# STM32G070 register map
File version: 1.4
CPU: CM0 r0p1, little endian, MPU, no FPU, 2 interrupt priority bits
Registers are 32-bit, read-write, reset 0x0 unless marked. A register's access mark holds for its fields unless they carry their own. Offsets are from the block's base; [hi:lo] are bit positions; {n}, {i} and the like mark numbered series.

## GPIOA — General-purpose I/Os
Base 0x50000000
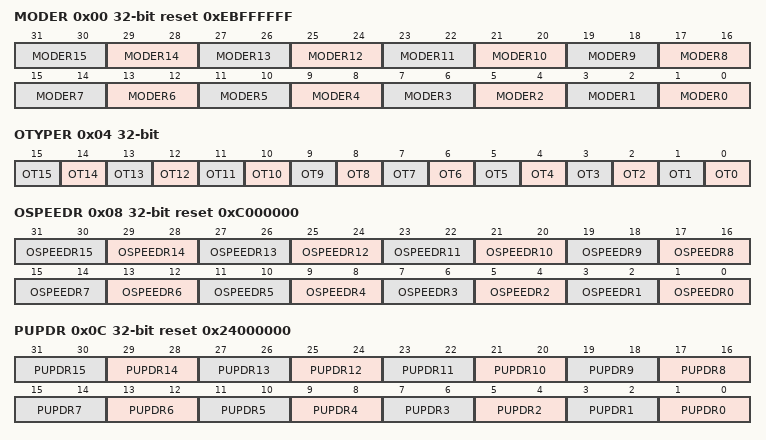
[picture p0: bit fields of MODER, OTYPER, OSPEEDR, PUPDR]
0x00 MODER reset 0xEBFFFFFF — GPIO port mode register
  [2n+1:2n] MODER{n} (n=0..15) — Port x configuration bits (y = 0..15)
0x04 OTYPER — GPIO port output type register
  [n] OT{n} (n=0..15) — Port x configuration bits (y = 0..15)
0x08 OSPEEDR reset 0xC000000 — GPIO port output speed register
  [2n+1:2n] OSPEEDR{n} (n=0..15) — Port x configuration bits (y = 0..15)
0x0C PUPDR reset 0x24000000 — GPIO port pull-up/pull-down register
  [2n+1:2n] PUPDR{n} (n=0..15) — Port x configuration bits (y = 0..15)
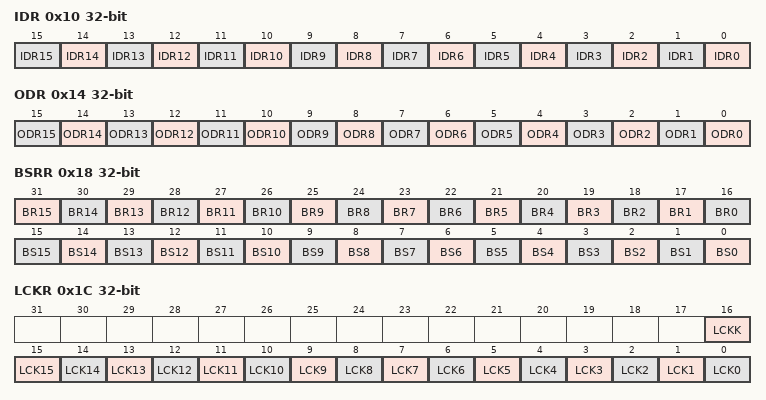
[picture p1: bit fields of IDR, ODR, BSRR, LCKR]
0x10 IDR ro — GPIO port input data register
  [n] IDR{n} (n=0..15) — Port input data (y = 0..15)
0x14 ODR — GPIO port output data register
  [n] ODR{n} (n=0..15) — Port output data (y = 0..15)
0x18 BSRR wo — GPIO port bit set/reset register
  [n+16] BR{n} (n=1..15) — Port x reset bit y (y = 0..15)
  [16] BR0 — Port x set bit y (y= 0..15)
  [n] BS{n} (n=0..15) — Port x set bit y (y= 0..15)
0x1C LCKR — GPIO port configuration lock register
  [16] LCKK — Port x lock bit y (y= 0..15)
  [n] LCK{n} (n=0..15) — Port x lock bit y (y= 0..15)
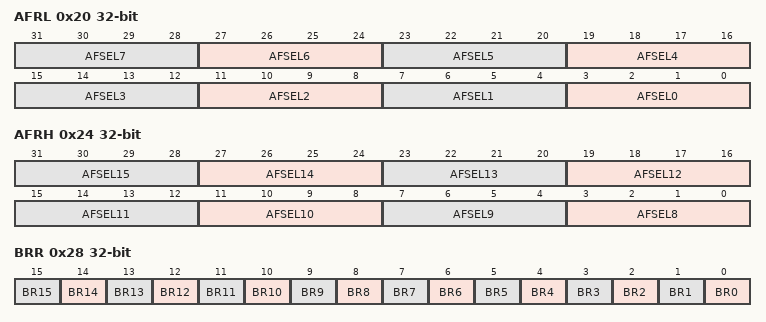
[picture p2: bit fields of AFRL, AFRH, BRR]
0x20 AFRL — GPIO alternate function low register
  [4n+3:4n] AFSEL{n} (n=0..7) — Alternate function selection for port x bit y (y = 0..7)
0x24 AFRH — GPIO alternate function high register
  [4n-29:4n-32] AFSEL{n} (n=8..15) — Alternate function selection for port x bit y (y = 8..15)
0x28 BRR wo — port bit reset register
  [n] BR{n} (n=0..15) — Port Reset bit

## GPIOB — General-purpose I/Os
Base 0x50000400
Same registers: GPIOC 0x50000800, GPIOD 0x50000C00, GPIOF 0x50001400
Registers as GPIOA; these are added or differ:
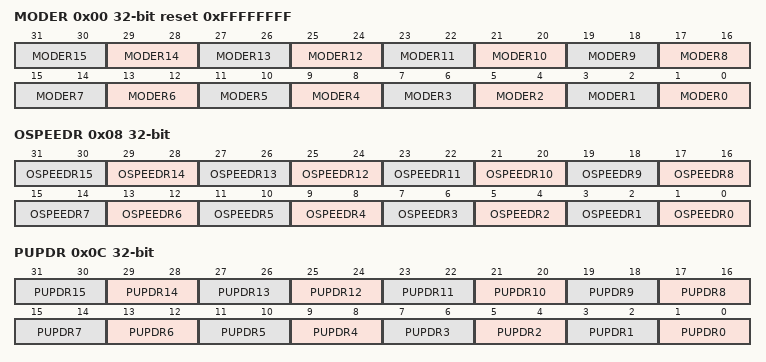
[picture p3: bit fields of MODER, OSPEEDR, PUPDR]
0x00 MODER reset 0xFFFFFFFF — GPIO port mode register
  [2n+1:2n] MODER{n} (n=0..15) — Port x configuration bits (y = 0..15)
0x08 OSPEEDR — GPIO port output speed register
  [2n+1:2n] OSPEEDR{n} (n=0..15) — Port x configuration bits (y = 0..15)
0x0C PUPDR — GPIO port pull-up/pull-down register
  [2n+1:2n] PUPDR{n} (n=0..15) — Port x configuration bits (y = 0..15)

## CRC — Cyclic redundancy check calculation unit
Base 0x40023000
0x00 DR reset 0xFFFFFFFF — Data register
  [31:0] DR — Data register bits
0x04 IDR — Independent data register
  [31:0] IDR — General-purpose 32-bit data register bits
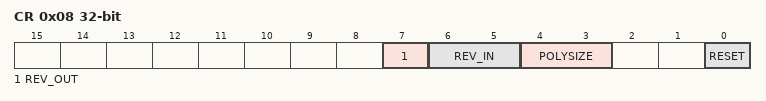
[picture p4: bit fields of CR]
0x08 CR access per field — Control register
  [7] REV_OUT rw — Reverse output data
  [6:5] REV_IN rw — Reverse input data
  [4:3] POLYSIZE rw — Polynomial size
  [0] RESET wo — RESET bit
0x10 INIT reset 0xFFFFFFFF — Initial CRC value
  [31:0] CRC_INIT — Programmable initial CRC value
0x14 POL reset 0x4C11DB7 — polynomial
  [31:0] POL — Programmable polynomial

## SPI1 — Serial peripheral interface/Inter-IC sound
Base 0x40013000
Same registers: SPI2 0x40003800
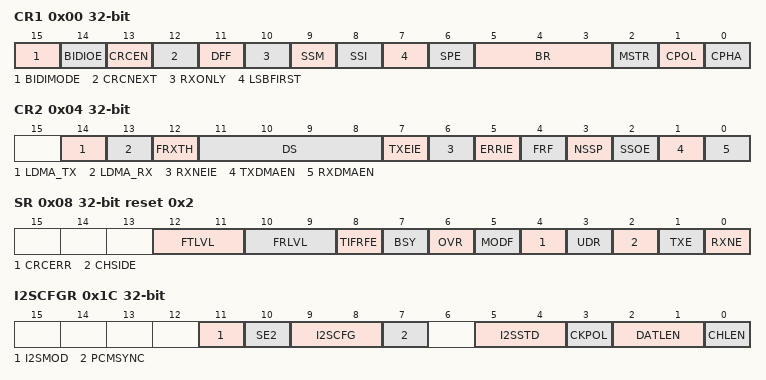
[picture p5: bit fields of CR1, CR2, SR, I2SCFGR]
0x00 CR1 — control register 1
  [15] BIDIMODE — Bidirectional data mode enable
  [14] BIDIOE — Output enable in bidirectional mode
  [13] CRCEN — Hardware CRC calculation enable
  [12] CRCNEXT — CRC transfer next
  [11] DFF — Data frame format
  [10] RXONLY — Receive only
  [9] SSM — Software slave management
  [8] SSI — Internal slave select
  [7] LSBFIRST — Frame format
  [6] SPE — SPI enable
  [5:3] BR — Baud rate control
  [2] MSTR — Master selection
  [1] CPOL — Clock polarity
  [0] CPHA — Clock phase
0x04 CR2 — control register 2
  [14] LDMA_TX — Last DMA transfer for transmission
  [13] LDMA_RX — Last DMA transfer for reception
  [12] FRXTH — FIFO reception threshold
  [11:8] DS — Data size
  [7] TXEIE — Tx buffer empty interrupt enable
  [6] RXNEIE — RX buffer not empty interrupt enable
  [5] ERRIE — Error interrupt enable
  [4] FRF — Frame format
  [3] NSSP — NSS pulse management
  [2] SSOE — SS output enable
  [1] TXDMAEN — Tx buffer DMA enable
  [0] RXDMAEN — Rx buffer DMA enable
0x08 SR access per field reset 0x2 — status register
  [12:11] FTLVL ro — FIFO transmission level
  [10:9] FRLVL ro — FIFO reception level
  [8] TIFRFE ro — TI frame format error
  [7] BSY ro — Busy flag
  [6] OVR ro — Overrun flag
  [5] MODF ro — Mode fault
  [4] CRCERR rw — CRC error flag
  [3] UDR ro — Underrun flag
  [2] CHSIDE ro — Channel side
  [1] TXE ro — Transmit buffer empty
  [0] RXNE ro — Receive buffer not empty
0x0C DR — data register
  [15:0] DR — Data register
0x10 CRCPR reset 0x7 — CRC polynomial register
  [15:0] CRCPOLY
0x14 RXCRCR ro — RX CRC register
  [15:0] RxCRC
0x18 TXCRCR ro — TX CRC register
  [15:0] TxCRC
0x1C I2SCFGR — configuration register
  [11] I2SMOD — I2S mode selection
  [10] SE2 — I2S enable
  [9:8] I2SCFG — I2S configuration mode
  [7] PCMSYNC — PCM frame synchronization
  [5:4] I2SSTD — standard selection
  [3] CKPOL — Inactive state clock polarity
  [2:1] DATLEN — Data length to be transferred
  [0] CHLEN — Channel length (number of bits per audio channel)
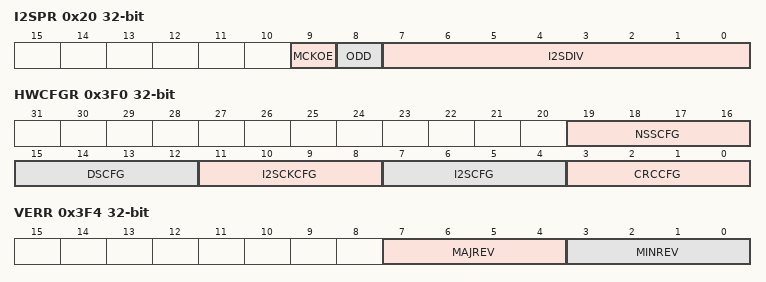
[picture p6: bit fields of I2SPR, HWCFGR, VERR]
0x20 I2SPR — prescaler register
  [9] MCKOE — Master clock output enable
  [8] ODD — Odd factor for the prescaler
  [7:0] I2SDIV — linear prescaler
0x3F0 HWCFGR ro — hardware configuration register
  [19:16] NSSCFG — NSS pulse feature enhancement at SPI master
  [15:12] DSCFG — SPI data size configuration
  [11:8] I2SCKCFG — I2S master clock generator at I2S mode
  [7:4] I2SCFG — I2S mode implementation
  [3:0] CRCCFG — CRC capable at SPI mode
0x3F4 VERR ro — EXTI IP Version register
  [7:4] MAJREV — Major Revision number
  [3:0] MINREV — Minor Revision number
0x3F8 IPIDR ro — EXTI Identification register
  [31:0] IPID — IP Identification
0x3FC SIDR ro — EXTI Size ID register
  [31:0] SID — Size Identification
